# DDR0_CTLPHY_WRAP_PHY_CFG register map
Vendor: Texas Instruments
Peripheral module from a debugger description file (folder am65x).
Registers are 32-bit, access per field, reset 0x0 unless marked. A register's access mark holds for its fields unless they carry their own. Offsets are as the file gives them; lines under a group give offsets from that group; [hi:lo] are bit positions; {n}, {i} and the like mark numbered series; 'fields as' and 'values as' point back to an identical list; <NAME> marks a mode.

## DDR0_CTLPHY_WRAP_PHY_CFG (part 1 of 4)
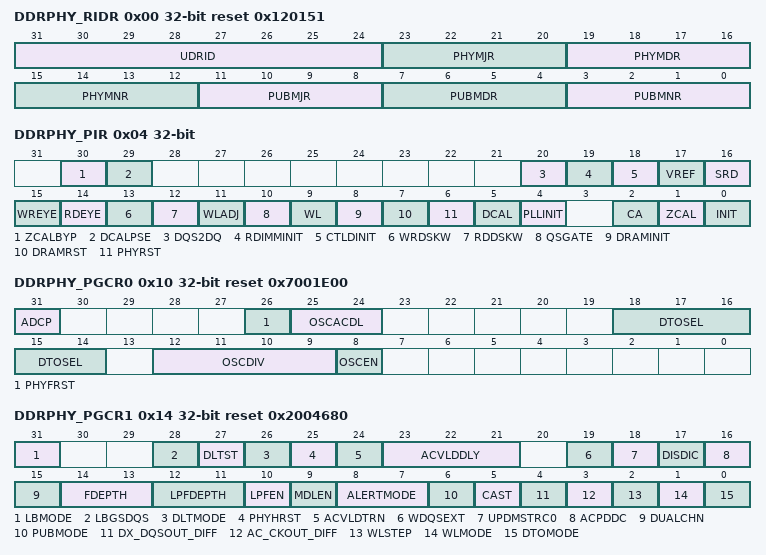
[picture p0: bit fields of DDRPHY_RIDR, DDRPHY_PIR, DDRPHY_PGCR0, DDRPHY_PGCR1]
0x00 DDRPHY_RIDR ro reset 0x120151 — Revision Identification Register
  [31:24] UDRID — User-Defined Revision ID: General purpose revision identification set by the user.
  [23:20] PHYMJR — PHY Major Revision: Indicates major revision of the PHY such addition of the features that make the new version not compatible with previous versions.
  [19:16] PHYMDR — PHY Moderate Revision: Indicates moderate revision of the PHY such as addition of new features. Normally the new version is still compatible with previous versions.
  [15:12] PHYMNR — PHY Minor Revision: Indicates minor update of the PHY such as bug fixes. Normally no new features are included.
  [11:8] PUBMJR — PUB Major Revision: Indicates major revision of the PUB such addition of the features that make the new version not compatible with previous versions.
  [7:4] PUBMDR — PUB Moderate Revision: Indicates moderate revision of the PUB such as addition of new features. Normally the new version is still compatible with previous versions.
  [3:0] PUBMNR — PUB Minor Revision: Indicates minor update of the PUB such as bug fixes. Normally no new features are included.
0x04 DDRPHY_PIR access not given — PHY Initialization Register
  [30] ZCALBYP — Impedance Calibration Bypass: Bypasses or stops, if set, impedance calibration of all ZQ control blocks that automatically triggers after reset. Impedance calibration may be triggered manually using INIT and ZCAL bits of the DDRPHY_PIR register. This bit is self-clearing. (access RW1C)
  [29] DCALPSE — Digital Delay Line (DDL) Calibration Pause: Pauses or halts, if set, DDL calibration. Clearing this bit will restart DDL calibrations. DDL calibration may be triggered manually using INIT and DCAL bits of the DDRPHY_PIR register. This bit should be set to 0 during DFI low power operation. (access RW1C)
  [20] DQS2DQ rw — Write DQS2DQ training: Executes a PUB training routine that compensates the clock tree delay (tDQS2DQ) in memory devices
  [19] RDIMMINIT rw — RDIMM Initialization: Executes the RDIMM buffer chip initialization before executing DRAM initialization. The RDIMM buffer chip initialization is run after the DRAM is reset and CKE have been driven high by the DRAM initialization sequence
  [18] CTLDINIT rw — Controller DRAM Initialization: Indicates if set that DRAM initialization will be performed by the controller. Otherwise if not set it indicates that DRAM initialization will be performed using the built-in initialization sequence or using software through the configuration port.
  [17] VREF rw — VREF training: Executes a PUB training routine for DRAM and HOST DQ I/O VREF values to enhance the write and read eye position. PUB automatically sets the RDMODE=2’b11 (static read mode) during this training. User must ensure that RDDLY settings are programmed correctly or remains at the default value.
  [16] SRD rw — Reserved, read/write bit, should only be written to 0.
  [15] WREYE rw — Write Data Eye Training: Executes a PUB training routine to maximize the write data eye.
  [14] RDEYE rw — Read Data Eye Training: Executes a PUB training routine to maximize the read data eye.
  [13] WRDSKW rw — Write Data Bit Deskew: Executes a PUB training routine to deskew the DQ bits during write.
  [12] RDDSKW rw — Read Data Bit Deskew: Executes a PUB training routine to deskew the DQ bits during read.
  [11] WLADJ rw — Write Leveling Adjust: Executes a PUB training routine that readjusts the write latency used during write in case the write leveling routine changed the expected latency.
  [10] QSGATE rw — Read DQS Gate Training: Executes a PUB training routine to determine the optimum position of the read data DQS strobe for maximum system timing margins.
  [9] WL rw — Write Leveling: Executes a PUB write leveling routine.
  [8] DRAMINIT rw — DRAM Initialization: Executes the DRAM initialization sequence.
  [7] DRAMRST rw — DRAM Reset (DDR3/DDR4/LPDDR4 Only): Issues a reset to the DRAM (by driving the DRAM reset pin low) and wait 200us. This can be triggered in isolation or with the full DRAM initialization (DRAMINIT). For the later case, the reset is issued and 200us is waited before starting the full initialization sequence.
  [6] PHYRST rw — PHY Reset: Resets the AC and DATX8 modules by asserting the AC/DATX8 reset pin.
  [5] DCAL rw — Digital Delay Line (DDL) Calibration: Performs PHY delay line calibration. If maintaining valid DRAM data and state through this calibration is required, then the DRAM should be put into self refresh before setting this bit to trigger the calibration; Before accessing the DRAM device, it should be removed from Self-Refresh after the calibration is completed.
  [4] PLLINIT rw — PLL Initialization: Executes the PLL initialization sequence which includes correct driving of PLL power-down, reset and gear shift pins, and then waiting for the PHY PLLs to lock.
  [2] CA rw — CA Training: Performs PHY LPDDR3 CA training. When set theLPDDR3 CA training will be performed after with PHY initialization (PLL initialization + DDL calibration + PHY reset).
  [1] ZCAL rw — Impedance Calibration: Executes impedance calibration
  [0] INIT — Initialization Trigger: A write of 1b1 to this bit triggers the DDR system initialization, including PHY initialization, DRAM initialization, and PHY training. The exact initialization steps to be executed are specified in bits 1 to 15 of this register. A bit setting of 1 means the step will be executed as part of the initialization sequence, while a setting of 1b0 means the step will be bypassed. The initialization trigger bit is self-clearing. It is recommended that this bit be set 1b1 in a separate config write step after other bits in this register have been programmed to avoid any race condition. The DDRPHY_PGSR0[IDONE] status bit indicates when the initialization steps are complete. Wait at least 32 DDRSS_PHY_CTL_CLK cycles after DDRPHY_PGSR0[IDONE] is observed to be 1b1 before starting or resuming traffic to DRAM. (access RW1C)
0x10 DDRPHY_PGCR0 reset 0x7001E00 — PHY General Configuration Register 0
  [31] ADCP rw — Address Copy:
  [26] PHYFRST rw — AC loopback read FIFO reset: A write of 1b0 to this bit resets the AC Macro FIFOs (in both AC macros, if 2 AC macros are present) without resetting PUB logic. This bit is not self-clearing and a 1b1 must be written to de-assert the reset.
  [25:24] OSCACDL rw — Oscillator Mode Address/Command Delay Line Select: Selects which of the two address/command LCDLs is active. The delay select value of the inactive LCDL is set to zero while the delay select value of the active LCDL can be varied by the input write leveling delay select pin. Valid values are:
  [18:14] DTOSEL rw — Digital Test Output Select: Selects the PHY digital test output that should be driven onto PHY digital test output (phy_dto) pin: Valid values are:
  [12:9] OSCDIV rw — Oscillator Mode Division for AC Macros: Specifies the factor by which the delay line oscillator mode output is divided down before it is output on the delay line digital test output pin dl_dto. Valid values are:
  [8] OSCEN rw — Oscillator Enable for AC Macros: Enables, if set, the delay line oscillation.
0x14 DDRPHY_PGCR1 access not given reset 0x2004680 — PHY General Configuration Register 1
  [31] LBMODE rw — Loopback Mode: Indicates, if set, that the PHY/PUB is in loopback mode.
  [28] LBGSDQS — Load GSDQS for DATX: Load GSDQS LCDL with 2x the calibrated GSDQSPRD value (equivalent to one CK period). This bit must only be used when initializing the GSDQS 180 degree offset for IO assisted gating mode. This bit is self clearing. (access RW1C)
  [27] DLTST rw — AC Delay Line Test Start: A write of 1b1 to this bit will trigger delay line oscillator mode period measurement. This bit is not self clearing and needs to be reset to 1b0 before the measurement can be re-triggered.
  [26] DLTMODE rw — AC Delay Line Test Mode: Selects, if set, the delay line oscillator test mode. Setting this bit also clears all delay line register values. For DL oscillator testing, first set this bit, then apply desired nonzero LCDL and BDL register programmings.
  [25] PHYHRST rw — PHY High-Speed Reset for AC macros: A write of 1b0 to this bit resets the AC macros without resetting PUB logic. This bit is not self-clearing and a 1b1 must be written to de-assert the reset.
  [24] ACVLDTRN rw — AC Loopback Valid Train: Indicates, if set, that AC loopback valid should be trained by the PUB before starting the AC loop-back BIST
  [23:21] ACVLDDLY rw — AC Loopback Valid Delay: Specifies the delay that should be applied to the AC loopback valid signal when in AC static read response.
  [19] WDQSEXT rw — When WDQS Extension mode is enabled by setting this bit to 1’b1:
  [18] UPDMSTRC0 rw — DFI Update Master Channel
  [17] DISDIC rw — Enable/Disable control for dfi Init complete
  [16] ACPDDC rw — AC Power-Down with Dual Channels: Set to 1 to power-down address/command lane when both data channels are powered-down. Only valid in Dual Channel Configuration (i.e when bit 28 is set).
  [15] DUALCHN rw — Dual Channel Configuration: Set to 1 to enable shared address/command mode with two independent data channels – available only if shared address/command mode is supported.
  [14:13] FDEPTH rw — Filter Depth: Specifies the number of measurements over which all AC and DATX8 initial period measurements, that happen after reset or when calibration is manually triggered, are averaged. Valid values are:
  [12:11] LPFDEPTH rw — Low-Pass Filter Depth: Specifies the number of measurements over which AC/DATX MDL period measurements are filtered. This determines the time constant of the low pass filter. Valid values are:
  [10] LPFEN rw — Low-Pass Filter Enable: Enables, if set, the low pass filtering AC/DATX MDL period measurements.
  [9] MDLEN rw — Master Delay Line Enable for AC: Enables, if set, the AC master delay line calibration to perform subsequent period measurements following the initial period measurements that are performed after reset or on when calibration is manually triggered. These additional measurements are accumulated and filtered as long as this bit remains high.
  [8:7] ALERTMODE rw — Used to control the dfi_alert_n signal sent to the Memory controller. Register encoding is as follows:
  [6] PUBMODE rw — Enables, if set, the PUB to control the interface to the PHY and SDRAM. In this mode the DFI commands from the controller are ignored. The bit must be set to 0 after the system determines it is convenient to pass control of the DFI bus to the controller. When set to 0 the DFI interface has control of the PHY and SDRAM interface except when triggering pub operations such as BIST, DCU(not supported) or data training.
  [5] CAST rw — CA software training. This bit must be set to 1 in order to perform CA software training. And must be set to 0 after the CA software training is complete.
  [4] DX_DQSOUT_DIFF rw — Selects PDQS cell for DQS generation 0 -&gt; Single ended IO used for generating DRAM DQS and DQS_N. [Default] 1 -&gt; Differential IO used for generating DRAM DQS and DQS_N. The DQS_N from DX macro is ignored by IO.
  [3] AC_CKOUT_DIFF rw — Selects PCK cell for CK generation 0 -&gt; Single ended IO used for generating DRAM CK and CK_N. [Default] 1 -&gt; Differential IO used for generating DRAM CK and CK_N. The CK_N from AC macro is ignored by IO.
  [2] WLSTEP rw — Write Leveling Step: Specifies the number of delay step-size increments during each step of write leveling. Valid values are:
  [1] WLMODE rw — Write Leveling (Software) Mode: Indicates if set that the PUB is in software write leveling mode in which software executes single steps of DQS pulsing by writing 1b1 to DDRPHY_PIR[WL]. The write leveling DQ status from the DRAM is captured in DDRPHY_DXnGSR0[WLDQ].
  [0] DTOMODE rw — Digital Test Output Mode: Selects whether the digital test outputs are coming from the PLL or the PHY (AC/DATX8) macros. Valid values are:
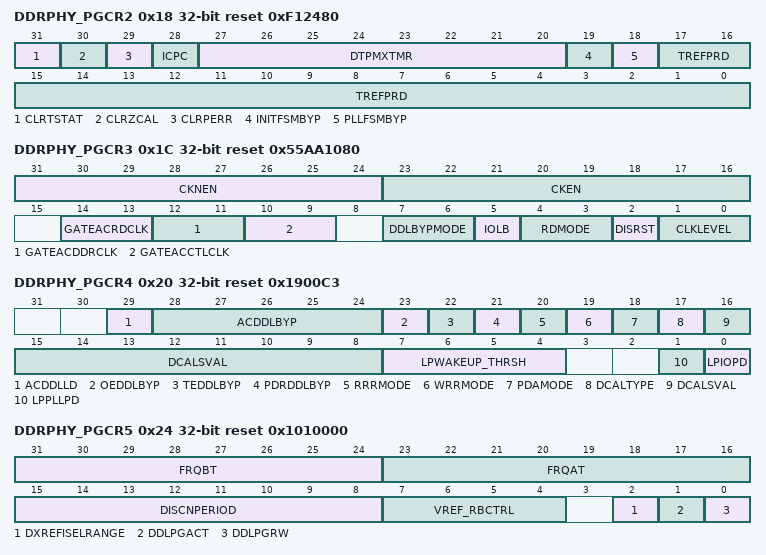
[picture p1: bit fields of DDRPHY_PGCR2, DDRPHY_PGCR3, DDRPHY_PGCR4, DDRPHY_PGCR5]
0x18 DDRPHY_PGCR2 access not given reset 0xF12480 — PHY General Configuration Register 2
  [31] CLRTSTAT — Clear Training Status Registers: A write of 1b1 to this bit will reset the error and done status bits for all training blocks (CA training, QS gate training, WL training, WLA training, read bit deskew, read eye centering, write bit deskew, write eye centering). This bit is self clearing. (access RW1C)
  [30] CLRZCAL — Clear Impedance Calibration: A write of 1b1 to this bit will reset the impedance calibration FSM and clear the DDRPHY_ZQnSR error/done status btis DDRPHY_ZQnSR[9:0]. This bit is self clearing. (access RW1C)
  [29] CLRPERR — Clear Parity Error: A write of 1b1 to this bit will clear the DDRPHY_PGSR1[31] PARERR. This bit is self clearing. (access RW1C)
  [28] ICPC rw — Initialization Complete Pin Configuration: Specifies how the DFI initialization complete output pin (dfi_init_complete) should be used to indicate the status of initialization. Valid value are:
  [27:20] DTPMXTMR rw — Data Training PUB Mode Exit Timer: Specifies the number of controller clocks to wait when entering and exiting pub mode data training. The default value ensures controller refreshes do not cause memory model errors when entering and exiting data training. The value should be increased if controller initiated SDRAM ZQ short or long operation may occur just before or just after the execution of data training.
  [19] INITFSMBYP rw — Initialization Bypass: Forces, if set, the Initialization FSMs to the DONE state. To be used for debug purposes only. This bit is not self-clearing so it must be cleared before triggering any operation in the DDRPHY_PIR.
  [18] PLLFSMBYP rw — PLL FSM Bypass: Forces, if set, the PLL FSM to the DONE state. This bit is not self-clearing so it must be cleared before triggering any operation in the DDRPHY_PIR. Set this bit to 1’b1 when PLL is in bypass mode.
  [17:0] TREFPRD rw — Refresh Period: Indicates the period in clock cycles after which the PUB has to issue a refresh command to the SDRAM. This is derived from the maximum refresh interval from the datasheet, tRFC(max) or REFI, divided by the clock cycle time. A further number of clocks must be subtracted from the derived number to account for command flow and missed slots of refreshes in the internal PUB blocks. In DDR3 and LPDDR3 mode, 400 clocks needs to subtracted In DDR4 and LPDDR4 mode, 800 clocks needs to subtracted In DDR3 and LPDDR3 mode, (DTCR.RFSHDT * tREFI)/tCK - 400 In DDR4 and LPDDR4 mode, (DTCR.RFSHDT * tREFI)/tCK - 800
0x1C DDRPHY_PGCR3 reset 0x55AA1080 — PHY General Configuration Register 3
  [31:24] CKNEN rw — CKN Enable: Controls whether the CKN going to the SDRAM is enabled (toggling) or disabled (static value) and whether the CKN is inverted. Two bits for each of the up to four CKN pairs. Valid values for the two bits are:
  [23:16] CKEN rw — CK Enable: Controls whether the CK going to the SDRAM is enabled (toggling) or disabled (static value) and whether the CK is inverted. Two bits for each of the up to four CK pairs. Valid values for the two bits are:
  [14:13] GATEACRDCLK rw — Enable Clock Gating for ctl_rd_clk of the AC Macros: Enables, when set, clock gating for power saving. Valid values are:
  [12:11] GATEACDDRCLK rw — Enable Clock Gating for DDRSS_BYP_4X_CLK of the AC Macros: Enables, when set, clock gating for power saving. Valid values are:
  [10:9] GATEACCTLCLK rw — Enable Clock Gating for DDRSS_PHY_CTL_CLK of the AC Macros: Enables, when set, clock gating for power saving. Valid values are:
  [7:6] DDLBYPMODE rw — Controls AC DDL Bypass Modes. Valid values are:
  [5] IOLB rw — AC I/O Loop-Back Select: Selects where inside the I/O the loop-back of signals happens. Valid values are:
  [4:3] RDMODE rw — AC Receive FIFO Read Mode. Valid values are:
  [2] DISRST rw — Disables the Read FIFO reset for AC macros: When set, read receive fifo cannot be reset from ctl_dx_rdfifo_rstn input. Valid values are:
  [1:0] CLKLEVEL rw — Selects the level to which clocks will be stalled when clock gating is enabled in AC macros. Valid values are:
0x20 DDRPHY_PGCR4 reset 0x1900C3 — PHY General Configuration Register 4
  [29] ACDDLLD rw — AC DDL Delay Select Dynamic Load: Specifies whether the registers inside the AC that hold the delay select signal of AC DDL should be dynamically loaded only when the delay select changes or should be continuously (always) loaded. This only applies to the AC delay LCDL. Valid values are:
  [28:24] ACDDLBYP rw — AC DDL Bypass: Specifies, if set to 1b1 that the DDL delay should be bypassed. Otherwise the DDL bypass is turned off. Different bits control different AC DDLs as follows: ACDDLBYP [0] = CKN BDL delay bypass ACDDLBYP [1] = CK BDL delay bypass ACDDLBYP [2] = Address/command BDL delay bypass ACDDLBYP [3] = Address/command LCDL delay bypass ACDDLBYP [4] = Master delay line LCDL delay bypass
  [23] OEDDLBYP rw — AC OE DDL Bypass: Specifies, if set to 1b1 that the DDL delay should be bypassed. Otherwise the DDL bypass is turned off
  [22] TEDDLBYP rw — AC ODT DDL Bypass: Specifies, if set to 1b1 that the DDL delay should be bypassed. Otherwise the DDL bypass is turned off
  [21] PDRDDLBYP rw — AC PDR DDL Bypass: Specifies, if set to 1b1 that the DDL delay should be bypassed. Otherwise the DDL bypass is turned off
  [20] RRRMODE rw — AC Macro Read Path Rise-to-Rise Mode: Indicates if set, that the PHY mission mode is configured to run in rise-to-rise mode for the read path. Otherwise if not set, the PHY mission mode for the read path is running in rise-to-fall mode.
  [19] WRRMODE rw — AC Macro Write Path Rise-to-Rise Mode: Indicates if set, that the PHY mission mode is configured to run in rise-to-rise mode for the write path. Otherwise if not set, the PHY mission mode for the write path is running in rise-to-fall mode.
  [18] PDAMODE rw — Set PDA mode timing. If this bit is set by the MCTL, the DFI write commands are delayed by 2 SDRAM clock cycles, while at the same time the DQ data is advanced with respect to DQS. This allows the MCTL to satisfy the t_PDA_S timing requirement. This register field must be set in conjunction with DX8SLnDQSCTL[15] for PDA mode to be properly enabled/disabled.
  [17] DCALTYPE rw — DDL Calibration Type: Select the algorithm in DDL Calibration. Select the algorithm as follows:
  [16:8] DCALSVAL rw — DDL Calibration Starting Value: Initial LCDL delay select value in DDL Calibration.
  [7:4] LPWAKEUP_THRSH rw — AC Low Power Wakeup Threshold: If dfi_lp_wakeup is greater than this threshold value, PLLs will be powered down when entering DFI low power mode. The value of the dfi_lp_wakeup signal at the time that the dfi_lp_ctrl_req or dfi_lp_data_req signal is asserted sets the tlp_wakeup time. Valid values in tems of number clock cycles are:
  [1] LPPLLPD rw — AC Low Power PLL Power Down: Specifies if set that the PHY should respond to the DFI low power opportunity request and power down the PLL of the byte if the wakeup time request satisfies the LPWAKEUP_THRSH. LPWAKEUP_THRSH is the Minimum threshold value of tlp_wakeup required to make PHY go into low power mode by powering down PLL. The value of the dfi_lp_wakeup signal at the time that the dfi_lp_data_req&amp;dfi_lp_ctrl_req signal is de-asserted sets the tlp_wakeup time. The value is in terms of number clock cycles.
  [0] LPIOPD rw — AC Low Power I/O Power Down: Specifies if set that the PHY should respond to the DFI low power opportunity request and power down the AC I/Os.
0x24 DDRPHY_PGCR5 reset 0x1010000 — PHY General Configuration Register 5
  [31:24] FRQBT rw — Frequency B Ratio Term: This 8-bit value represents the value of the term associated with the secondary operating frequency. The secondary operating frequency is associated with the fields in this register DDLPGRW/DDLPGACT with a setting of 1b1. Valid values are from 1 to 255
  [23:16] FRQAT rw — Frequency A Ratio Term: This 8-bit value represents the value of the term associated with the primary operating frequency. The primary operating frequency is associated with the fields in this register DDLPGRW/DDLPGACT with a setting of 1b0. Valid values are from 1 to 255
  [15:8] DISCNPERIOD rw — DFI Disconnect Time Period: Disconnect timer programmable value
  [7:4] VREF_RBCTRL rw — Receiver bias core side control
  [2] DXREFISELRANGE rw — Internal VREF generator range select. Values are:
  [1] DDLPGACT rw — This register field selects what register set to use.
  [0] DDLPGRW rw — This register field selects what register set to access for read/write.
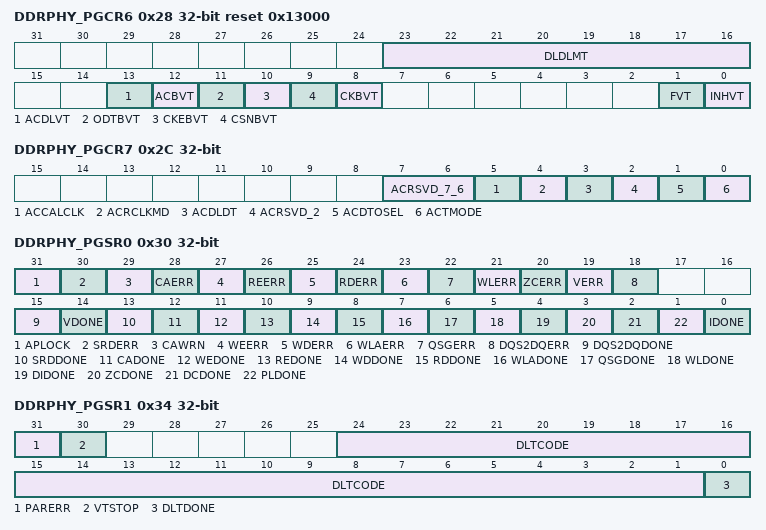
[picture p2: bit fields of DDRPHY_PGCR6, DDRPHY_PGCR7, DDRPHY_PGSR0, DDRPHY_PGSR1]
0x28 DDRPHY_PGCR6 reset 0x13000 — PHY General Configuration Register 6
  [23:16] DLDLMT rw — Delay Line VT Drift Limit
  [13] ACDLVT rw — AC Address/Command Delay LCDL VT Compensation: Enables, if set, the VT drift compensation of the address/command (ACD) LCDL.
  [12] ACBVT rw — Address/Command Bit Delay VT Compensation: Enables, if set the VT drift compensation of the address/command bit delay registers ACBLDR1,2,6,7,8,9,15. This bit doesn’t control VT compensation for CK, CSN, CKE and ODT BDLs.
  [11] ODTBVT rw — ODT Bit Delay VT Compensation: Enables, if set the VT drift compensation of the AC macro ODT bit delay registers ACBLDR4. The VT compensation of ODT may produce a glitch on the SDRAM ODT and should only be enabled if the SDRAM ODT is inactive.
  [10] CKEBVT rw — CKE Bit Delay VT Compensation: Enables, if set the VT drift compensation of the AC macro CKE bit delay registers ACBLDR5. The VT compensation of CKE may produce a glitch on the SDRAM CKE and should only be enabled if the SDRAM CKE is inactive.
  [9] CSNBVT rw — CSN Bit Delay VT Compensation: Enables, if set the VT drift compensation of the AC macro CSN bit delay registers ACBLDR3. The VT compensation of CSN may produce a glitch on the SDRAM CSN and should only be enabled if the SDRAM CSN is inactive.
  [8] CKBVT rw — CK/CKN Bit Delay VT Compensation: Enables, if set the VT drift compensation of the AC macro CK/CKN bit delay registers ACBLDR0.DDRPHY_ACBDLR16. The VT compensation of CK/CKN bdls may produce a glitch on the SDRAM CK/CKN and should only be enabled if the SDRAM CK/CKN is inactive.
  [1] FVT rw — Forced VT Compensation Trigger: When written to 1b1 a single VT update will be issued to all enabled slave BDLs and LCDLs. This bit is not self-clearing.
  [0] INHVT rw — VT Calculation Inhibit: Inhibits calculation of the next VT compensated delay line values. A value of 1 will initiate a stop of the VT compensation logic. The bit DDRPHY_PGSR1[30] (VSTOP) will be set to a logic x1 when VT compensation has stopped.This bit should be set to 1 during writes to the delay line registers. A value of 0 will re-enable the VT compensation logic.
0x2C DDRPHY_PGCR7 — PHY General Configuration Register 7
  [7:6] ACRSVD_7_6 rw — These bits are reserved for future AC special PHY modes but the registers are already connected to existing (unused) AC phy_mode bits.
  [5] ACCALCLK rw — AC Calibration Clock Select: Valid values are:
  [4] ACRCLKMD rw — AC read Clock Mode: Valid values are:
  [3] ACDLDT rw — AC DDL Load Type: Specifies how the delay select signal is applied to the AC delay lines. This is only applicable to DDLs that have their delay select signals pipelined, such address/command LCDL
  [2] ACRSVD_2 rw — This bit is reserved for future AC special PHY modes but the register is already connected to existing (unused) AC phy_mode bits.
  [1] ACDTOSEL rw — AC Digital Test Output Select: This is used to select the AC internal signals that should be driven on the two AC digital test outputs (phy_status[1:0]) signals. Valid values for AC digital test output bit 0 (phy_status[0]) are:
  [0] ACTMODE rw — AC Test Mode: This is used to enable special test mode in the AC macro. Valid values are:
0x30 DDRPHY_PGSR0 ro — PHY General Status Register 0
  [31] APLOCK — AC PLL Lock: Indicates, if set, that the AC PLL has locked. This is a direct status of the AC PLL lock pin.
  [30] SRDERR — Static Read Error: Indicates if set that there is an error in static read training. Static read training not supported in this release.
  [29] CAWRN — CA Training Warning: Indicates if set that there is a warning in LPDDR3 CA training.
  [28] CAERR — CA Training Error: Indicates if set that there is an error in LPDDR3 CA training.
  [27] WEERR — Write Eye Training Error: Indicates if set that there is an error in write eye training.
  [26] REERR — Read Eye Training Error: Indicates if set that there is an error in read eye training.
  [25] WDERR — Write Bit Deskew Error: Indicates if set that there is an error in write bit deskew.
  [24] RDERR — Read Bit Deskew Error: Indicates if set that there is an error in read bit deskew.
  [23] WLAERR — Write Leveling Adjustment Error: Indicates if set that there is an error in write leveling adjustment.
  [22] QSGERR — DQS Gate Training Error: Indicates if set that there is an error in DQS gate training.
  [21] WLERR — Write Leveling Error: Indicates if set that there is an error in write leveling.
  [20] ZCERR — Impedance Calibration Error: Indicates if set that there is an error in impedance calibration.
  [19] VERR — VREF Training Error: Indicates if set that there is and error in VREF training.
  [18] DQS2DQERR — Write DQS2DQ training Error: Indicates if set that there is an error in DQS2DQ training.
  [15] DQS2DQDONE — Write DQS2DQ training done. Indicates if set that write DQS2DQ training has completed.
  [14] VDONE — VREF Training Done: Indicates if set that DRAM and Host VREF training has completed.
  [13] SRDDONE — Static Read Done: Indicates if set that static read training has completed. Static read training not supported in this release.
  [12] CADONE — CA Training Done: Indicates if set that LPDDR3 CA training has completed.
  [11] WEDONE — Write Eye Training Done: Indicates if set that write eye training has completed.
  [10] REDONE — Read Eye Training Done: Indicates if set that read eye training has completed.
  [9] WDDONE — Write Bit Deskew Done: Indicates if set that write bit deskew has completed.
  [8] RDDONE — Read Bit Deskew Done: Indicates if set that read bit deskew has completed.
  [7] WLADONE — Write Leveling Adjustment Done: Indicates if set that write leveling adjustment has completed.
  [6] QSGDONE — DQS Gate Training Done: Indicates if set that DQS gate training has completed.
  [5] WLDONE — Write Leveling Done: Indicates if set that write leveling has completed.
  [4] DIDONE — DRAM Initialization Done: Indicates if set that DRAM initialization has completed.
  [3] ZCDONE — Impedance Calibration Done: Indicates if set that impedance calibration has completed.
  [2] DCDONE — Digital Delay Line (DDL) Calibration Done: Indicates if set that DDL calibration has completed.
  [1] PLDONE — PLL Lock Done: Indicates if set that PLL locking has completed.
  [0] IDONE — Initialization Done: Indicates if set that the DDR system initialization has completed. This bit is set after all the selected initialization routines in DDRPHY_PIR register have completed. Wait at least 32 DDRSS_PHY_CTL_CLK cycles after this is first observed to be 1b1 before starting/resuming traffic to DRAM or triggering new DDRPHY_PIR[INIT].
0x34 DDRPHY_PGSR1 ro — PHY General Status Register 1
  [31] PARERR — RDIMM Parity Error: Indicates, if set, that there was a parity error (i.e. err_out_n/alert_n was sampled low) during one of the transactions to the RDIMM buffer chip or DDR4 DRAM device. This bit remains asserted until cleared by the DDRPHY_PIR[CLRSR].
  [30] VTSTOP — VT Stop: Indicates if set that the VT calculation logic has stopped computing the next values for the VT compensated delay line values. After assertion of the DDRPHY_PGCR6[INHVT], the VTSTOP bit should be read to ensure all VT compensation logic has stopped computations before writing to the delay line registers.
  [24:1] DLTCODE — Delay Line Test Code for AC macro 0:
  [0] DLTDONE — Delay Line Test Done for AC macro 0:
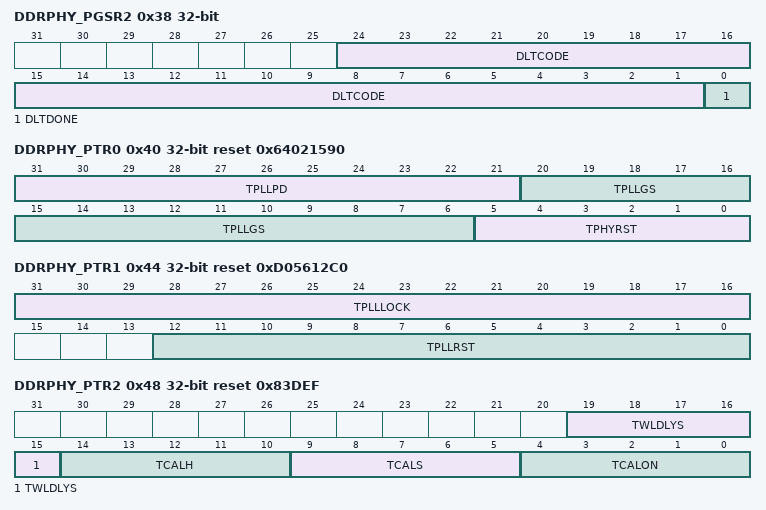
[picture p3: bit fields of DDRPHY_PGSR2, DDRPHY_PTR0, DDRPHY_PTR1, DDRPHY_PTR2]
0x38 DDRPHY_PGSR2 ro — PHY General Status Register 2
  [24:1] DLTCODE — Delay Line Test Code for AC macro 1:
  [0] DLTDONE — Delay Line Test Done for AC macro 1:
0x40 DDRPHY_PTR0 rw reset 0x64021590 — PHY Timing Register 0
  [31:21] TPLLPD — PLL Power-Down Time: Number of DDRSS_PHY_CTL_CLK cycles that the PLL must remain in power-down mode, i.e. number of clock cycles from when PLL power-down pin is asserted to when PLL power-down pin is de-asserted. This must correspond to a value that is equal to or more than 1us. Default value corresponds to 1us at 1600 MHz DRAM clock.
  [20:6] TPLLGS — PLL Gear Shift Time: Number of DDRSS_PHY_CTL_CLK cycles from when the PLL reset pin is de-asserted to when the PLL gear shift pin is de-asserted. This must correspond to a value that is equal to or more than 4us.
  [5:0] TPHYRST — PHY Reset Time: Number of DDRSS_PHY_CTL_CLK cycles that the PHY reset must remain asserted after PHY calibration is done before the reset to the PHY is de-asserted. This is used to extend the reset to the PHY so that the reset is asserted for some clock cycles after the clocks are stable. Valid values are 5’d1-5’d63.
0x44 DDRPHY_PTR1 reset 0xD05612C0 — PHY Timing Register 1
  [31:16] TPLLLOCK rw — PLL Lock Time: Number of DDRSS_PHY_CTL_CLK cycles for the PLL to stabilize and lock, i.e. number of clock cycles from when the PLL reset pin is de-asserted to when the PLL has lock and is ready for use. This must correspond to a value that is equal to or more than 25us at 1600MHz DRAM clock.
  [12:0] TPLLRST rw — PLL Reset Time: Number of DDRSS_PHY_CTL_CLK cycles that the PLL must remain in reset mode, i.e. number of clock cycles from when PLL power-down pin is de-asserted and PLL reset pin is asserted to when PLL reset pin is de-asserted. This must correspond to a value that is equal to or more than 9us.
0x48 DDRPHY_PTR2 reset 0x83DEF — PHY Timing Register 2
  [19:15] TWLDLYS rw — Programming value (number of controller clock cycles) in this register adds the delay from the end of tWLDQSEN time to the first rising edge of DQS. This is used in Write Level Training Only.
  [14:10] TCALH rw — Calibration Hold Time: Number of controller clock cycles from when the clock was disabled (cal_clk_en de-asserted) to when calibration is enable (cal_en asserted). The default value is the recommended minimum value.
  [9:5] TCALS rw — Calibration Setup Time: Number of controller clock cycles from when calibration is enabled (cal_en asserted) to when the calibration clock is asserted again (cal_clk_en asserted).). The default value is the recommended minimum value.
  [4:0] TCALON rw — Calibration On Time: Number of controller clock cycles that the calibration clock is enabled (cal_clk_en asserted). The default value is the recommended minimum value.
0x4C DDRPHY_PTR3 reset 0x411810 — PHY Timing Register 3
  [22:0] TDINIT0 rw — DRAM Initialization Time 0:
0x50 DDRPHY_PTR4 reset 0x10AA — PHY Timing Register 4
  [12:0] TDINIT1 rw — DRAM Initialization Time 1:
0x54 DDRPHY_PTR5 reset 0x68268 — PHY Timing Register 5
  [18:0] TDINIT2 rw — DRAM Initialization Time 2:
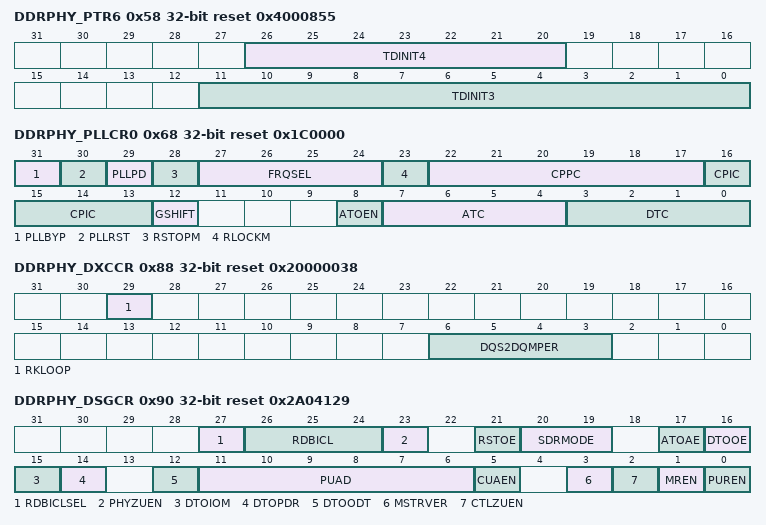
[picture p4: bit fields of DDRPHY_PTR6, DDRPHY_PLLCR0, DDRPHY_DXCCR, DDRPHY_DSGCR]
0x58 DDRPHY_PTR6 reset 0x4000855 — PHY Timing Register 6
  [26:20] TDINIT4 rw — DRAM Initialization Time 4:
  [11:0] TDINIT3 rw — DRAM Initialization Time 3:
0x68 DDRPHY_PLLCR0 reset 0x1C0000 — PLL Control Register 0 (Type B PLL Only)
  [31] PLLBYP rw — PLL Bypass: Bypasses the PLL if set to 1b1.
  [30] PLLRST rw — PLL Rest: Resets the PLLs by driving the PLL reset pin. This bit is not self-clearing and a 1b0 must be written to de-assert the reset.
  [29] PLLPD rw — PLL Power Down: Puts the PLLs in power down mode by driving the PLL power down pin. This bit is not self-clearing and a 1b0 must be written to de-assert the power-down.
  [28] RSTOPM rw — Reference Stop Mode. Connects to pin REF_STOP_MODE. Valid values are:
  [27:24] FRQSEL rw — PLL Frequency Select: Selects the operating range of the PLL. Settings are specific to PLL type.
  [23] RLOCKM rw — Relock Mode: Enables, if set, rapid relocking mode.
  [22:17] CPPC rw — Charge Pump Proportional Current Control. Connects to pin CPPROP_CTRL on the PLL. Valid values are:
  [16:13] CPIC rw — Charge Pump Integrating Current Control. Connects to pin CP_INT_CTRL on the PLL. Valid values are:
  [12] GSHIFT rw — Gear Shift: Enables, if set, rapid locking mode. Connects to pin GEAR_SHIFT on the PLL.
  [8] ATOEN rw — Analog Test Enable (ATOEN): Selects the analog test signal that should be driven on the analog test output pin. Otherwise the analog test output is tri-stated. This allows analog test output pins from multiple PLLs to be connected together. Valid values are:
  [7:4] ATC rw — Analog Test Control: Controls PLL input pins pll_ana_test_sel[3:0]. Selects various PLL analog test signals to be brought out via PLL analog test output pin (pll_ato).
  [3:0] DTC rw — Digital Test Control: Controls PLL input pins pll_dig_test_sel. Selects various PLL digital test signals and other test mode signals to be brought out via bit [1] of the PLL digital test output (pll_dto[1]).
0x88 DDRPHY_DXCCR reset 0x20000038 — DATX8 Common Configuration Register
  [29] RKLOOP rw — Rank looping (per-rank eye centering) enable. Enables, if set, the read and write eye centering algorithms to be executed in a loop for all the system ranks, storing individual LCDL centering values for each rank. If this bit is not set, read and write centering are only executed for the configured DDRPHY_DTCR0. DTRANK, although the result is replicated to all rank LCDLs
  [6:3] DQS2DQMPER rw — Write DQS2DQ training measurement period: Sets the tDQS2DQ delay measurement period. Valid values for measurement period are:
0x90 DDRPHY_DSGCR reset 0x2A04129 — DDR System General Configuration Register
  [27] RDBICLSEL rw — When RDBI enabled, this bit is used to select RDBI CL calculation, if it is 1, calculation will use RDBICL, otherwise use default calculation. This is applicable only in DDR4 mode.
  [26:24] RDBICL rw — When RDBI enabled, if RDBICLSEL is asserted, RDBI CL adjust using this value. This is applicable only in DDR4 mode.
  [23] PHYZUEN rw — PHY Impedance Update Enable: Specifies, if set, that in addition to DDL VT update, the PHY should also perform impedance calibration (update) whenever there is a DFI update request from the PHY.
  [21] RSTOE rw — SDRAM Reset Output Enable: Enables, when set, the output driver on the I/O for SDRAM RST# pin.
  [20:19] SDRMODE rw — Single Data Rate Mode: Indicates if the controller or the PHY is configured to run in single data rate (SDR) mode. The default is both the controller and the PHY running in half data rate (HDR) mode. Valid values are:
  [17] ATOAE rw — ATO Analog Test Enable: Enables, if set, the analog test output (ATO) I/O.
  [16] DTOOE rw — DTO Output Enable: Enables, when set, the output driver on the I/O for DTO pins.
  [15] DTOIOM rw — DTO I/O Mode: Selects SSTL mode (when set to 0) or CMOS mode (when set to 1) of the I/O for DTO pins.
  [14] DTOPDR rw — DTO Power Down Receiver: Powers down, when set, the input receiver on the I/O for DTO pins.
  [12] DTOODT rw — DTO On-Die Termination: Enables, when set, the on-die termination on the I/O for DTO pins.
  [11:6] PUAD rw — PHY Update Acknowledge Delay: Specifies the number of clock cycles that the indication for the completion of PHY update from the PHY to the controller should be delayed. This essentially delays the de-assertion of dfi_ctrlup_ack and dfi_phyupd_req signals by 2* PUAD clocks relative to the time when the delay lines or I/Os are updated.
  [5] CUAEN rw — Controller Update Acknowledge Enable: Specifies, if set, that the PHY should issue controller update acknowledge when the DFI controller update request is asserted. By default the PHY sends acknowledge for controller initiated update requests.
  [3] MSTRVER rw — Master version: This field indicates the version of the PHY Master Interface currently in use.
  [2] CTLZUEN rw — Controller Impedance Update Enable: Specifies, if set, that in addition to DDL VT update, the PHY should also perform impedance calibration (update) whenever there is a DFI update request.
  [1] MREN rw — Master Request Enable. When set HIGH, PHY will generate DFI PHY Master Request when any internal block requests for the DFI bus and expects an ACK from the controller in return.
  [0] PUREN rw — PHY Update Request Enable: Specifies if set, that the PHY should issue PHY-initiated update request when there is DDL VT drift.
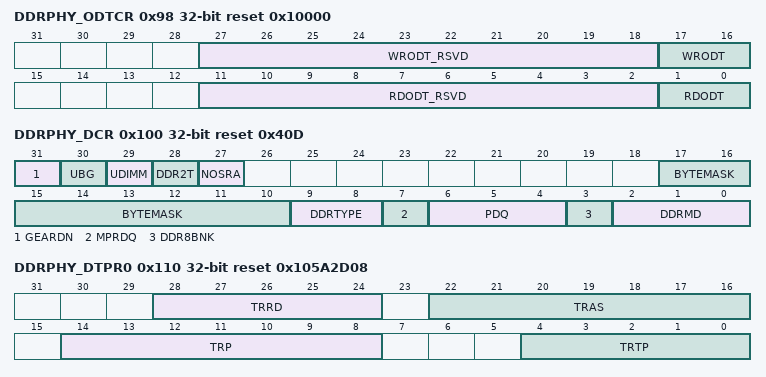
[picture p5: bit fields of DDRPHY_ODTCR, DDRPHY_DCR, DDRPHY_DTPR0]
0x98 DDRPHY_ODTCR reset 0x10000 — ODT Configuration Register
  [27:18] WRODT_RSVD ro — Reserved.Return zeroes on reads.
  [17:16] WRODT rw — Write ODT.
  [11:2] RDODT_RSVD ro — Reserved.Return zeroes on reads.
  [1:0] RDODT rw — Read ODT.
0xC0 DDRPHY_GPR0 rw — General Purpose Register 0
  [31:0] GPR0 — General Purpose Register 0: General purpose register bits.
0xC4 DDRPHY_GPR1 rw — General Purpose Register 1
  [31:0] GPR1 — General Purpose Register 1: General purpose register bits.
0x100 DDRPHY_DCR reset 0x40D — DRAM Configuration Register
  [31] GEARDN rw — DDR4 Gear Down timing If set, the PUB will generate AC bus signals to the SDRAM with a modified 2-cycle (2T) timing, lining the signals with the rising edge of the SDRAM clock instead of in quadrature to it.
  [30] UBG rw — Un-used Bank Group: Indicates if set that BG[1] pin of PHY is unused and not connected to the memory (for example, UDIMM x16). In such scenario, Output Enable for BG[1] IO may be disabled from DDRPHY_ACIOCR3[BGOEMODE] register field.
  [29] UDIMM rw — Un-buffered DIMM Address Mirroring: Indicates if set that there is address mirroring on the second rank of an unbuffered DIMM (the rank connected to CS#[1]). In this case, the PUB re-scrambles the bank and address when sending mode register commands to the second rank. This only applies to PUB internal SDRAM transactions. Transactions generated by the controller must make its own adjustments when using an un-buffered DIMM. DDRPHY_DCR[NOSRA] must be set if address mirroring is enabled.
  [28] DDR2T rw — DDR 2T Timing: Indicates if set that 2T timing should be used by PUB internally generated SDRAM transactions. This bit should be programmed to 1b0 during AC bist loopback or when used with LPDDR3 or LPDDR4 DRAMs.
  [27] NOSRA rw — No Simultaneous Rank Access: Specifies if set that simultaneous rank access on the same clock cycle is not allowed. This means that multiple chip select signals should not be asserted at the same time. This may be required on some DIMM systems.
  [17:10] BYTEMASK rw — Byte Mask: Mask applied to all beats of read data on all bytes lanes during read DQS gate training. This allows training to be conducted based on selected bit(s) from the byte lanes.Note that this mask applies in DDR3 MPR operation mode as well and must be in keeping with the PDQ field setting.
  [9:8] DDRTYPE rw — DDR Type: Selects the DDR type for the specified DDR mode.
  [7] MPRDQ rw — Multi-Purpose Register (MPR) DQ: Specifies the value that is driven on non-primary DQ pins during MPR reads. Valid values are:
  [6:4] PDQ rw — Primary DQ: Specifies the DQ pin in a byte that is designated as a primary pin for Multi-Purpose Register (MPR) reads. Valid values are 0 to 7 for DQ[0] to DQ[7] respectively.
  [3] DDR8BNK rw — DDR 8-Bank: Indicates if set that the SDRAM used has 8 banks. tRPA = tRP+1 and tFAW are used for 8-bank DRAMs, other tRPA = tRP and no tFAW is used. Note that a setting of 1 for DRAMs that have fewer than 8 banks still results in correct functionality but less tighter DRAM command spacing for the parameters described here.
  [2:0] DDRMD rw — DDR Mode: SDRAM DDR mode. Valid values are:
0x110 DDRPHY_DTPR0 reset 0x105A2D08 — DRAM Timing Parameters Register 0
  [28:24] TRRD rw — Activate to activate command delay (different banks). Valid values are 1 to 31. For DDR4, use tRRD_L (RAS-to-RAS delay for same bank group). Larger values give more conservative command-tocommand timings.
  [22:16] TRAS rw — Activate to precharge command delay. Larger values give more conservative command-to-command timings.
  [14:8] TRP rw — Precharge command period: The minimum time between a precharge command and any other command. In LPDDR3 mode, set this parameter as per tRPab(slow) - max(27ns,3nCK). Also in LPDDR3 mode, PUB adds an offset of 8 to the register value. For all other protocols, set to the min specified value of tRP. Larger values give more conservative command-to-command timings.
  [4:0] TRTP rw — Internal minimum read to precharge command delay for DDR3 and LPDDR3 modes. Valid values are 2 to 15. Larger values give more conservative command-to-command timings. In DDR4/LPDDR4 mode, tRTP is decoded based on corresponding MR register fields; this field is unused (don’tcare). DDR 4: Uses MR0[13], MR0[11:9] instead LPDDR4: Uses MR2[2:0] instead
